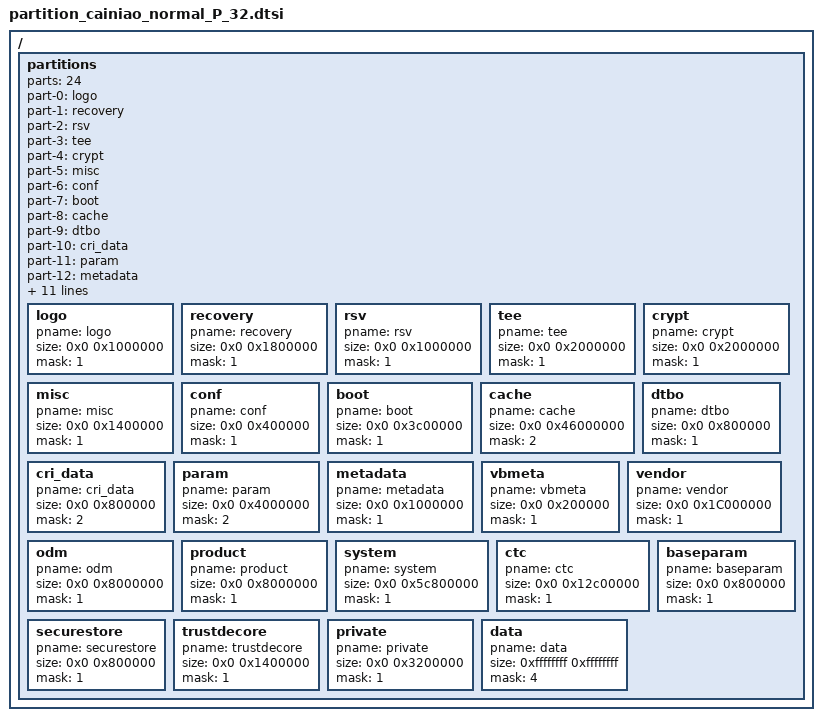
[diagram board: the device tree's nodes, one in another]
#include "firmware_system.dtsi"

/ {
    partitions: partitions{
                parts = <24>;
                part-0 = <&logo>;
                part-1 = <&recovery>;
                part-2 = <&rsv>;
                part-3 = <&tee>;
                part-4 = <&crypt>;
                part-5 = <&misc>;
                part-6 = <&conf>;
                part-7 = <&boot>;
                part-8 = <&cache>;
                part-9 = <&dtbo>;
                part-10 = <&cri_data>;
                part-11 = <&param>;
                part-12 = <&metadata>;
                part-13 = <&vbmeta>;
                part-14 = <&vendor>;
                part-15 = <&odm>;
                part-16 = <&product>;
                part-17 = <&system>;
                part-18 = <&ctc>;
                part-19 = <&baseparam>;
                part-20 = <&securestore>;
                part-21 = <&trustdecore>;
                part-22 = <&private>;
                part-23 = <&data>;

                logo:logo{
                        pname = "logo";
                        size = <0x0 0x1000000>;
                        mask = <1>;
                };
                recovery:recovery{
                        pname = "recovery";
                        size = <0x0 0x1800000>;
                        mask = <1>;
                };
                rsv:rsv{
                        pname = "rsv";
                        size = <0x0 0x1000000>;
                        mask = <1>;
                };
                tee:tee{
                        pname = "tee";
                        size = <0x0 0x2000000>;
                        mask = <1>;
                };
                crypt:crypt{
                        pname = "crypt";
                        size = <0x0 0x2000000>;
                        mask = <1>;
                };
                misc:misc{
                        pname = "misc";
                        size = <0x0 0x1400000>;
                        mask = <1>;
                };
                conf:conf{
                        pname = "conf";
                        size = <0x0 0x400000>;
                        mask = <1>;
                };
                boot:boot{
                        pname = "boot";
                        size = <0x0 0x3c00000>;
                        mask = <1>;
                };
                cache:cache{
                        pname = "cache";
                        size = <0x0 0x46000000>;
                        mask = <2>;
                };
                dtbo:dtbo{
                        pname = "dtbo";
                        size = <0x0 0x800000>;
                        mask = <1>;
                };
                cri_data:cri_data{
                        pname = "cri_data";
                        size = <0x0 0x800000>;
                        mask = <2>;
                };
                param:param{
                        pname = "param";
                        size = <0x0 0x4000000>;
                        mask = <2>;
                };
                metadata:metadata{
                        pname = "metadata";
                        size = <0x0 0x1000000>;
                        mask = <1>;
                };
                vbmeta:vbmeta{
                        pname = "vbmeta";
                        size = <0x0 0x200000>;
                        mask = <1>;
                };
                vendor:vendor{
                        pname = "vendor";
                        size = <0x0 0x1C000000>;
                        mask = <1>;
                };
                odm:odm{
                        pname = "odm";
                        size = <0x0 0x8000000>;
                        mask = <1>;
                };
                product:product{
                        pname = "product";
                        size = <0x0 0x8000000>;
                        mask = <1>;
                };
                system:system{
                        pname = "system";
                        size = <0x0 0x5c800000>;
                        mask = <1>;
                };
                ctc:ctc{
                        pname = "ctc";
                        size = <0x0 0x12c00000>;
                        mask = <1>;
                };
                baseparam:baseparam{
                        pname = "baseparam";
                        size = <0x0 0x800000>;
                        mask = <1>;
                };
                securestore:securestore{
                        pname = "securestore";
                        size = <0x0 0x800000>;
                        mask = <1>;
                };
                trustdecore:trustdecore{
                        pname = "trustdecore";
                        size = <0x0 0x1400000>;
                        mask = <1>;
                };
                private:private{
                        pname = "private";
                        size = <0x0 0x3200000>;
                        mask = <1>;
                };
                data:data{
                        pname = "data";
                        size = <0xffffffff 0xffffffff>;
                        mask = <4>;
                };
        };
};
